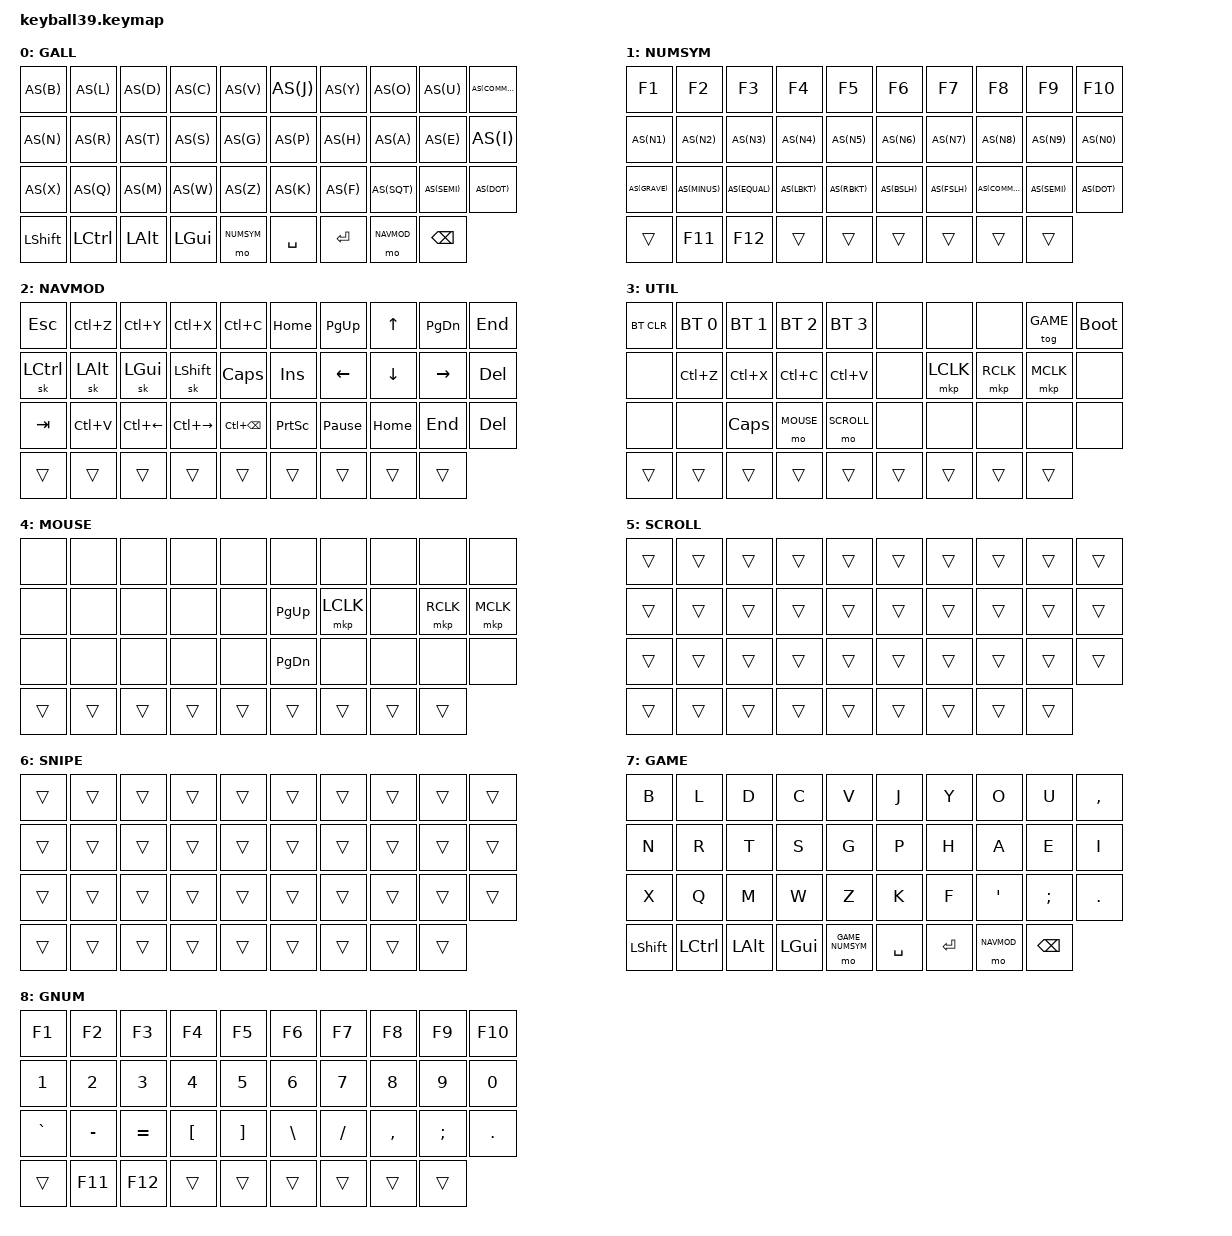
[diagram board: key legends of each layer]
#define BASE    0
#define NUMSYM  1
#define NAVMOD  2
#define UTIL    3
#define MOUSE   4
#define SCROLL  5
#define SNIPE   6
#define GAME    7
#define GAME_NUMSYM 8

#include <behaviors/mouse_keys.dtsi>
#include <dt-bindings/zmk/mouse.h>
#include <behaviors.dtsi>
#include <dt-bindings/zmk/bt.h>
#include <dt-bindings/zmk/keys.h>

#define AS(keycode) &as LS(keycode) keycode

/ {
    combos {
        compatible = "zmk,combos";

        combo_bspc {
            timeout-ms = <50>;
            key-positions = <6 7>;
            bindings = <&kp BACKSPACE>;
        };
    };

    behaviors {
        as: auto_shift {
            compatible = "zmk,behavior-hold-tap";
            #binding-cells = <2>;
            tapping-term-ms = <135>;
            quick-tap-ms = <0>;
            flavor = "tap-preferred";
            bindings = <&kp>, <&kp>;
        };
    };

    conditional_layers {
        compatible = "zmk,conditional-layers";
        util_tri_layer {
            if-layers = <NUMSYM NAVMOD>;
            then-layer = <UTIL>;
        };
    };

    keymap {
        compatible = "zmk,keymap";

        base_layer {
            label = "GALL";
            bindings = <
AS(B)       AS(L)       AS(D)        AS(C)         AS(V)                         AS(J)           AS(Y)           AS(O)           AS(U)           AS(COMMA)
AS(N)       AS(R)       AS(T)        AS(S)         AS(G)                         AS(P)           AS(H)           AS(A)           AS(E)           AS(I)
AS(X)       AS(Q)       AS(M)        AS(W)         AS(Z)                         AS(K)           AS(F)           AS(SQT)         AS(SEMI)        AS(DOT)
&kp LSHIFT  &kp LCTRL   &kp LALT     &kp LGUI      &mo NUMSYM   &kp SPACE        &kp ENTER       &mo NAVMOD      &kp BACKSPACE
            >;
        };

        numsym_layer {
            label = "NUMSYM";
            bindings = <
&kp F1      &kp F2      &kp F3       &kp F4        &kp F5                        &kp F6          &kp F7          &kp F8          &kp F9          &kp F10
AS(N1)      AS(N2)      AS(N3)       AS(N4)        AS(N5)                        AS(N6)          AS(N7)          AS(N8)          AS(N9)          AS(N0)
AS(GRAVE)   AS(MINUS)   AS(EQUAL)    AS(LBKT)      AS(RBKT)                      AS(BSLH)        AS(FSLH)        AS(COMMA)       AS(SEMI)        AS(DOT)
&trans      &kp F11     &kp F12      &trans        &trans                        &trans          &trans          &trans          &trans
            >;
        };

        navmod_layer {
            label = "NAVMOD";
            bindings = <
&kp ESC     &kp LC(Z)   &kp LC(Y)    &kp LC(X)     &kp LC(C)                     &kp HOME        &kp PG_UP       &kp UP          &kp PG_DN       &kp END
&sk LCTRL   &sk LALT    &sk LGUI     &sk LSHFT     &kp CAPS                      &kp INS         &kp LEFT        &kp DOWN        &kp RIGHT       &kp DEL
&kp TAB     &kp LC(V)   &kp LC(LEFT) &kp LC(RIGHT) &kp LC(BSPC)                 &kp PSCRN       &kp PAUSE_BREAK &kp HOME        &kp END         &kp DEL
&trans      &trans      &trans       &trans        &trans                        &trans          &trans          &trans          &trans
            >;
        };

        util_layer {
            label = "UTIL";
            bindings = <
&bt BT_CLR  &bt BT_SEL 0 &bt BT_SEL 1 &bt BT_SEL 2  &bt BT_SEL 3                  &none           &none           &none           &tog GAME       &bootloader
&none       &kp LC(Z)    &kp LC(X)    &kp LC(C)     &kp LC(V)                     &none           &mkp LCLK       &mkp RCLK       &mkp MCLK       &none
&none       &none        &kp CAPS     &mo MOUSE     &mo SCROLL                    &none           &none           &none           &none           &none
&trans      &trans       &trans       &trans        &trans                        &trans          &trans          &trans          &trans
            >;
        };

        mouse_layer {
            label = "MOUSE";
            bindings = <
&none       &none        &none        &none         &none                         &none           &none           &none           &none           &none
&none       &none        &none        &none         &none                         &kp PG_UP       &mkp LCLK       &none           &mkp RCLK       &mkp MCLK
&none       &none        &none        &none         &none                         &kp PG_DN       &none           &none           &none           &none
&trans      &trans       &trans       &trans        &trans                        &trans          &trans          &trans          &trans
            >;
        };

        scroll_layer {
            label = "SCROLL";
            bindings = <
&trans  &trans  &trans  &trans  &trans                  &trans  &trans  &trans  &trans  &trans
&trans  &trans  &trans  &trans  &trans                  &trans  &trans  &trans  &trans  &trans
&trans  &trans  &trans  &trans  &trans                  &trans  &trans  &trans  &trans  &trans
&trans  &trans  &trans  &trans  &trans  &trans  &trans  &trans  &trans
            >;
        };

        snipe_layer {
            label = "SNIPE";
            bindings = <
&trans  &trans  &trans  &trans  &trans                  &trans  &trans  &trans  &trans  &trans
&trans  &trans  &trans  &trans  &trans                  &trans  &trans  &trans  &trans  &trans
&trans  &trans  &trans  &trans  &trans                  &trans  &trans  &trans  &trans  &trans
&trans  &trans  &trans  &trans  &trans  &trans  &trans  &trans  &trans
            >;
        };

        game_layer {
            label = "GAME";
            bindings = <
&kp B       &kp L       &kp D        &kp C         &kp V                          &kp J           &kp Y           &kp O           &kp U           &kp COMMA
&kp N       &kp R       &kp T        &kp S         &kp G                          &kp P           &kp H           &kp A           &kp E           &kp I
&kp X       &kp Q       &kp M        &kp W         &kp Z                          &kp K           &kp F           &kp SQT         &kp SEMI        &kp DOT
&kp LSHIFT  &kp LCTRL   &kp LALT     &kp LGUI      &mo GAME_NUMSYM &kp SPACE     &kp ENTER       &mo NAVMOD      &kp BACKSPACE
            >;
        };

        game_numsym_layer {
            label = "GNUM";
            bindings = <
&kp F1      &kp F2      &kp F3       &kp F4        &kp F5                        &kp F6          &kp F7          &kp F8          &kp F9          &kp F10
&kp N1      &kp N2      &kp N3       &kp N4        &kp N5                        &kp N6          &kp N7          &kp N8          &kp N9          &kp N0
&kp GRAVE   &kp MINUS   &kp EQUAL    &kp LBKT      &kp RBKT                      &kp BSLH        &kp FSLH        &kp COMMA       &kp SEMI        &kp DOT
&trans      &kp F11     &kp F12      &trans        &trans                        &trans          &trans          &trans          &trans
            >;
        };
    };
};
